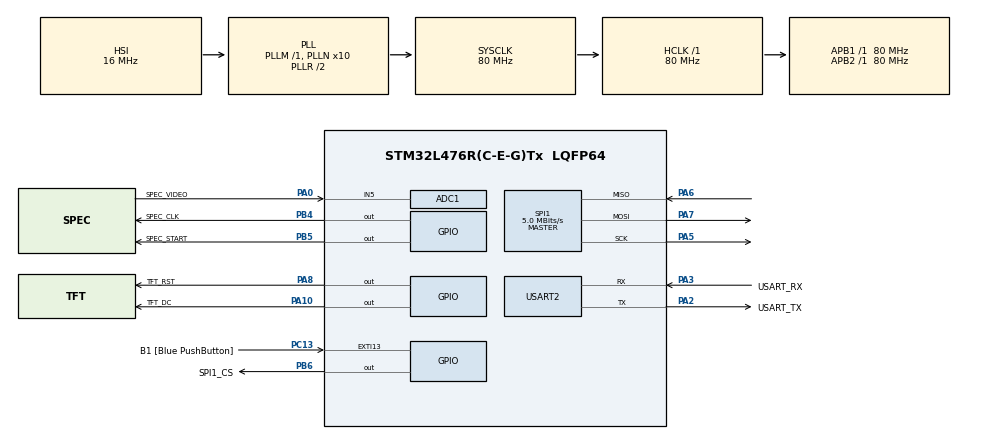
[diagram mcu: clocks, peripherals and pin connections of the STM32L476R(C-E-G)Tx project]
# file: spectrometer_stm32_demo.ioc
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ADC1.Channel-0\#ChannelRegularConversion=ADC_CHANNEL_5
ADC1.NbrOfConversionFlag=1
ADC1.OffsetNumber-0\#ChannelRegularConversion=ADC_OFFSET_NONE
ADC1.Rank-0\#ChannelRegularConversion=1
ADC1.SamplingTime-0\#ChannelRegularConversion=ADC_SAMPLETIME_2CYCLES_5
ADC1.master=1
Mcu.Family=STM32L4
Mcu.Name=STM32L476R(C-E-G)Tx
Mcu.Package=LQFP64
NVIC.PriorityGroup=NVIC_PRIORITYGROUP_4
PA0.GPIO_Label=SPEC_VIDEO
PA0.Signal=ADCx_IN5
PA10.GPIO_Label=TFT_DC
PA10.Signal=GPIO_Output
PA13\ (JTMS-SWDIO).GPIO_Label=TMS
PA13\ (JTMS-SWDIO).Mode=Serial_Wire
PA13\ (JTMS-SWDIO).Signal=SYS_JTMS-SWDIO
PA14\ (JTCK-SWCLK).GPIO_Label=TCK
PA14\ (JTCK-SWCLK).Mode=Serial_Wire
PA14\ (JTCK-SWCLK).Signal=SYS_JTCK-SWCLK
PA2.GPIO_Label=USART_TX
PA2.GPIO_Mode=GPIO_MODE_AF_PP
PA2.GPIO_PuPd=GPIO_NOPULL
PA2.GPIO_Speed=GPIO_SPEED_FREQ_VERY_HIGH
PA2.Mode=Asynchronous
PA2.Signal=USART2_TX
PA3.GPIO_Label=USART_RX
PA3.GPIO_Mode=GPIO_MODE_AF_PP
PA3.GPIO_PuPd=GPIO_NOPULL
PA3.GPIO_Speed=GPIO_SPEED_FREQ_VERY_HIGH
PA3.Mode=Asynchronous
PA3.Signal=USART2_RX
PA5.Mode=Full_Duplex_Master
PA5.Signal=SPI1_SCK
PA6.Mode=Full_Duplex_Master
PA6.Signal=SPI1_MISO
PA7.Mode=Full_Duplex_Master
PA7.Signal=SPI1_MOSI
PA8.GPIO_Label=TFT_RST
PA8.Signal=GPIO_Output
PB3\ (JTDO-TRACESWO).GPIO_Label=SWO
PB3\ (JTDO-TRACESWO).Signal=SYS_JTDO-SWO
PB4\ (NJTRST).GPIO_Label=SPEC_CLK
PB4\ (NJTRST).Signal=GPIO_Output
PB5.GPIO_Label=SPEC_START
PB5.Signal=GPIO_Output
PB6.GPIO_Label=SPI1_CS
PB6.Signal=GPIO_Output
PC13.GPIO_Label=B1 [Blue PushButton]
PC13.GPIO_ModeDefaultEXTI=GPIO_MODE_IT_FALLING
PC13.GPIO_PuPd=GPIO_NOPULL
PC13.Signal=GPXTI13
PC14-OSC32_IN\ (PC14).Mode=LSE-External-Oscillator
PC14-OSC32_IN\ (PC14).Signal=RCC_OSC32_IN
PC15-OSC32_OUT\ (PC15).Mode=LSE-External-Oscillator
PC15-OSC32_OUT\ (PC15).Signal=RCC_OSC32_OUT
PH0-OSC_IN\ (PH0).Signal=RCC_OSC_IN
PH1-OSC_OUT\ (PH1).Signal=RCC_OSC_OUT
ProjectManager.HeapSize=0x200
ProjectManager.StackSize=0x400
ProjectManager.TargetToolchain=STM32CubeIDE
RCC.ADCFreq_Value=64000000
RCC.AHBFreq_Value=80000000
RCC.APB1Freq_Value=80000000
RCC.APB1TimFreq_Value=80000000
RCC.APB2Freq_Value=80000000
RCC.APB2TimFreq_Value=80000000
RCC.CortexFreq_Value=80000000
RCC.HCLKFreq_Value=80000000
RCC.HSE_VALUE=8000000
RCC.HSI_VALUE=16000000
RCC.MSI_VALUE=4000000
RCC.PLLN=10
RCC.PLLSourceVirtual=RCC_PLLSOURCE_HSI
RCC.PREFETCH_ENABLE=1
RCC.SYSCLKFreq_VALUE=80000000
RCC.SYSCLKSource=RCC_SYSCLKSOURCE_PLLCLK
RCC.USBFreq_Value=64000000
RCC.VCOOutputFreq_Value=160000000
SH.ADCx_IN5.0=ADC1_IN5,IN5-Single-Ended
SPI1.BaudRatePrescaler=SPI_BAUDRATEPRESCALER_16
SPI1.CalculateBaudRate=5.0 MBits/s
SPI1.DataSize=SPI_DATASIZE_8BIT
SPI1.Direction=SPI_DIRECTION_2LINES
SPI1.Mode=SPI_MODE_MASTER
SPI1.NSSPMode=SPI_NSS_PULSE_DISABLE
SPI1.VirtualType=VM_MASTER
TIM2.Prescaler=80-1
USART2.VirtualMode-Asynchronous=VM_ASYNC
VP_TIM2_VS_ClockSourceINT.Mode=Internal
board=NUCLEO-L476RG

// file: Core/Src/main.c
/* USER CODE BEGIN Header */
/**
  ******************************************************************************
  * @file           : main.c
  * @brief          : Main program body
  ******************************************************************************
  * @attention
  *
  * <h2><center>&copy; Copyright (c) 2022 STMicroelectronics.
  * All rights reserved.</center></h2>
  *
  * This software component is licensed by ST under BSD 3-Clause license,
  * the "License"; You may not use this file except in compliance with the
  * License. You may obtain a copy of the License at:
  *                        opensource.org/licenses/BSD-3-Clause
  *
  ******************************************************************************
  */
/* USER CODE END Header */
#include "main.h"

/* USER CODE BEGIN Includes */
#include "ili9341_display.h"
#include "spectrometer.h"
/* USER CODE END Includes */

ADC_HandleTypeDef hadc1;

SPI_HandleTypeDef hspi1;

TIM_HandleTypeDef htim2;

UART_HandleTypeDef huart2;

void SystemClock_Config(void);
static void MX_GPIO_Init(void);
static void MX_USART2_UART_Init(void);
static void MX_SPI1_Init(void);
static void MX_TIM2_Init(void);
static void MX_ADC1_Init(void);

int main(void)
{

  /* MCU Configuration--------------------------------------------------------*/

  /* Reset of all peripherals, Initializes the Flash interface and the Systick. */
  HAL_Init();

  /* Configure the system clock */
  SystemClock_Config();

  /* Initialize all configured peripherals */
  MX_GPIO_Init();
  MX_USART2_UART_Init();
  MX_SPI1_Init();
  MX_TIM2_Init();
  MX_ADC1_Init();
  /* USER CODE BEGIN 2 */
  ILI9341_Init();
  //ILI9341_Set_Rotation(SCREEN_HORIZONTAL_1); //todo:!
  spectrometerInit();
  /* USER CODE END 2 */

  /* Infinite loop */
  while (1)
  {

    /* USER CODE BEGIN 3 */
	  runSpectrometer();
  }
  /* USER CODE END 3 */
}

void SystemClock_Config(void)
{
  RCC_OscInitTypeDef RCC_OscInitStruct = {0};
  RCC_ClkInitTypeDef RCC_ClkInitStruct = {0};
  RCC_PeriphCLKInitTypeDef PeriphClkInit = {0};

  /** Initializes the RCC Oscillators according to the specified parameters
  * in the RCC_OscInitTypeDef structure.
  */
  RCC_OscInitStruct.OscillatorType = RCC_OSCILLATORTYPE_HSI;
  RCC_OscInitStruct.HSIState = RCC_HSI_ON;
  RCC_OscInitStruct.HSICalibrationValue = RCC_HSICALIBRATION_DEFAULT;
  RCC_OscInitStruct.PLL.PLLState = RCC_PLL_ON;
  RCC_OscInitStruct.PLL.PLLSource = RCC_PLLSOURCE_HSI;
  RCC_OscInitStruct.PLL.PLLM = 1;
  RCC_OscInitStruct.PLL.PLLN = 10;
  RCC_OscInitStruct.PLL.PLLP = RCC_PLLP_DIV7;
  RCC_OscInitStruct.PLL.PLLQ = RCC_PLLQ_DIV2;
  RCC_OscInitStruct.PLL.PLLR = RCC_PLLR_DIV2;
  if (HAL_RCC_OscConfig(&RCC_OscInitStruct) != HAL_OK)
  {
    Error_Handler();
  }
  /** Initializes the CPU, AHB and APB buses clocks
  */
  RCC_ClkInitStruct.ClockType = RCC_CLOCKTYPE_HCLK|RCC_CLOCKTYPE_SYSCLK
                              |RCC_CLOCKTYPE_PCLK1|RCC_CLOCKTYPE_PCLK2;
  RCC_ClkInitStruct.SYSCLKSource = RCC_SYSCLKSOURCE_PLLCLK;
  RCC_ClkInitStruct.AHBCLKDivider = RCC_SYSCLK_DIV1;
  RCC_ClkInitStruct.APB1CLKDivider = RCC_HCLK_DIV1;
  RCC_ClkInitStruct.APB2CLKDivider = RCC_HCLK_DIV1;

  if (HAL_RCC_ClockConfig(&RCC_ClkInitStruct, FLASH_LATENCY_4) != HAL_OK)
  {
    Error_Handler();
  }
  PeriphClkInit.PeriphClockSelection = RCC_PERIPHCLK_USART2|RCC_PERIPHCLK_ADC;
  PeriphClkInit.Usart2ClockSelection = RCC_USART2CLKSOURCE_PCLK1;
  PeriphClkInit.AdcClockSelection = RCC_ADCCLKSOURCE_PLLSAI1;
  PeriphClkInit.PLLSAI1.PLLSAI1Source = RCC_PLLSOURCE_HSI;
  PeriphClkInit.PLLSAI1.PLLSAI1M = 1;
  PeriphClkInit.PLLSAI1.PLLSAI1N = 8;
  PeriphClkInit.PLLSAI1.PLLSAI1P = RCC_PLLP_DIV7;
  PeriphClkInit.PLLSAI1.PLLSAI1Q = RCC_PLLQ_DIV2;
  PeriphClkInit.PLLSAI1.PLLSAI1R = RCC_PLLR_DIV2;
  PeriphClkInit.PLLSAI1.PLLSAI1ClockOut = RCC_PLLSAI1_ADC1CLK;
  if (HAL_RCCEx_PeriphCLKConfig(&PeriphClkInit) != HAL_OK)
  {
    Error_Handler();
  }
  /** Configure the main internal regulator output voltage
  */
  if (HAL_PWREx_ControlVoltageScaling(PWR_REGULATOR_VOLTAGE_SCALE1) != HAL_OK)
  {
    Error_Handler();
  }
}

static void MX_ADC1_Init(void)
{

  ADC_MultiModeTypeDef multimode = {0};
  ADC_ChannelConfTypeDef sConfig = {0};

  /** Common config
  */
  hadc1.Instance = ADC1;
  hadc1.Init.ClockPrescaler = ADC_CLOCK_ASYNC_DIV1;
  hadc1.Init.Resolution = ADC_RESOLUTION_12B;
  hadc1.Init.DataAlign = ADC_DATAALIGN_RIGHT;
  hadc1.Init.ScanConvMode = ADC_SCAN_DISABLE;
  hadc1.Init.EOCSelection = ADC_EOC_SINGLE_CONV;
  hadc1.Init.LowPowerAutoWait = DISABLE;
  hadc1.Init.ContinuousConvMode = DISABLE;
  hadc1.Init.NbrOfConversion = 1;
  hadc1.Init.DiscontinuousConvMode = DISABLE;
  hadc1.Init.ExternalTrigConv = ADC_SOFTWARE_START;
  hadc1.Init.ExternalTrigConvEdge = ADC_EXTERNALTRIGCONVEDGE_NONE;
  hadc1.Init.DMAContinuousRequests = DISABLE;
  hadc1.Init.Overrun = ADC_OVR_DATA_PRESERVED;
  hadc1.Init.OversamplingMode = DISABLE;
  if (HAL_ADC_Init(&hadc1) != HAL_OK)
  {
    Error_Handler();
  }
  /** Configure the ADC multi-mode
  */
  multimode.Mode = ADC_MODE_INDEPENDENT;
  if (HAL_ADCEx_MultiModeConfigChannel(&hadc1, &multimode) != HAL_OK)
  {
    Error_Handler();
  }
  /** Configure Regular Channel
  */
  sConfig.Channel = ADC_CHANNEL_5;
  sConfig.Rank = ADC_REGULAR_RANK_1;
  sConfig.SamplingTime = ADC_SAMPLETIME_2CYCLES_5;
  sConfig.SingleDiff = ADC_SINGLE_ENDED;
  sConfig.OffsetNumber = ADC_OFFSET_NONE;
  sConfig.Offset = 0;
  if (HAL_ADC_ConfigChannel(&hadc1, &sConfig) != HAL_OK)
  {
    Error_Handler();
  }

}

static void MX_SPI1_Init(void)
{

  /* SPI1 parameter configuration*/
  hspi1.Instance = SPI1;
  hspi1.Init.Mode = SPI_MODE_MASTER;
  hspi1.Init.Direction = SPI_DIRECTION_2LINES;
  hspi1.Init.DataSize = SPI_DATASIZE_8BIT;
  hspi1.Init.CLKPolarity = SPI_POLARITY_LOW;
  hspi1.Init.CLKPhase = SPI_PHASE_1EDGE;
  hspi1.Init.NSS = SPI_NSS_SOFT;
  hspi1.Init.BaudRatePrescaler = SPI_BAUDRATEPRESCALER_16;
  hspi1.Init.FirstBit = SPI_FIRSTBIT_MSB;
  hspi1.Init.TIMode = SPI_TIMODE_DISABLE;
  hspi1.Init.CRCCalculation = SPI_CRCCALCULATION_DISABLE;
  hspi1.Init.CRCPolynomial = 7;
  hspi1.Init.CRCLength = SPI_CRC_LENGTH_DATASIZE;
  hspi1.Init.NSSPMode = SPI_NSS_PULSE_DISABLE;
  if (HAL_SPI_Init(&hspi1) != HAL_OK)
  {
    Error_Handler();
  }

}

static void MX_TIM2_Init(void)
{

  TIM_ClockConfigTypeDef sClockSourceConfig = {0};
  TIM_MasterConfigTypeDef sMasterConfig = {0};

  htim2.Instance = TIM2;
  htim2.Init.Prescaler = 80-1;
  htim2.Init.CounterMode = TIM_COUNTERMODE_UP;
  htim2.Init.Period = 4294967295;
  htim2.Init.ClockDivision = TIM_CLOCKDIVISION_DIV1;
  htim2.Init.AutoReloadPreload = TIM_AUTORELOAD_PRELOAD_DISABLE;
  if (HAL_TIM_Base_Init(&htim2) != HAL_OK)
  {
    Error_Handler();
  }
  sClockSourceConfig.ClockSource = TIM_CLOCKSOURCE_INTERNAL;
  if (HAL_TIM_ConfigClockSource(&htim2, &sClockSourceConfig) != HAL_OK)
  {
    Error_Handler();
  }
  sMasterConfig.MasterOutputTrigger = TIM_TRGO_RESET;
  sMasterConfig.MasterSlaveMode = TIM_MASTERSLAVEMODE_DISABLE;
  if (HAL_TIMEx_MasterConfigSynchronization(&htim2, &sMasterConfig) != HAL_OK)
  {
    Error_Handler();
  }
  /* USER CODE BEGIN TIM2_Init 2 */
  HAL_TIM_Base_Start (&htim2);
  /* USER CODE END TIM2_Init 2 */

}

static void MX_USART2_UART_Init(void)
{

  huart2.Instance = USART2;
  huart2.Init.BaudRate = 115200;
  huart2.Init.WordLength = UART_WORDLENGTH_8B;
  huart2.Init.StopBits = UART_STOPBITS_1;
  huart2.Init.Parity = UART_PARITY_NONE;
  huart2.Init.Mode = UART_MODE_TX_RX;
  huart2.Init.HwFlowCtl = UART_HWCONTROL_NONE;
  huart2.Init.OverSampling = UART_OVERSAMPLING_16;
  huart2.Init.OneBitSampling = UART_ONE_BIT_SAMPLE_DISABLE;
  huart2.AdvancedInit.AdvFeatureInit = UART_ADVFEATURE_NO_INIT;
  if (HAL_UART_Init(&huart2) != HAL_OK)
  {
    Error_Handler();
  }

}

static void MX_GPIO_Init(void)
{
  GPIO_InitTypeDef GPIO_InitStruct = {0};

  /* GPIO Ports Clock Enable */
  __HAL_RCC_GPIOC_CLK_ENABLE();
  __HAL_RCC_GPIOH_CLK_ENABLE();
  __HAL_RCC_GPIOA_CLK_ENABLE();
  __HAL_RCC_GPIOB_CLK_ENABLE();

  /*Configure GPIO pin Output Level */
  HAL_GPIO_WritePin(GPIOA, TFT_RST_Pin|TFT_DC_Pin, GPIO_PIN_RESET);

  /*Configure GPIO pin Output Level */
  HAL_GPIO_WritePin(GPIOB, SPEC_CLK_Pin|SPEC_START_Pin|SPI1_CS_Pin, GPIO_PIN_RESET);

  /*Configure GPIO pin : B1_Pin */
  GPIO_InitStruct.Pin = B1_Pin;
  GPIO_InitStruct.Mode = GPIO_MODE_IT_FALLING;
  GPIO_InitStruct.Pull = GPIO_NOPULL;
  HAL_GPIO_Init(B1_GPIO_Port, &GPIO_InitStruct);

  /*Configure GPIO pins : TFT_RST_Pin TFT_DC_Pin */
  GPIO_InitStruct.Pin = TFT_RST_Pin|TFT_DC_Pin;
  GPIO_InitStruct.Mode = GPIO_MODE_OUTPUT_PP;
  GPIO_InitStruct.Pull = GPIO_NOPULL;
  GPIO_InitStruct.Speed = GPIO_SPEED_FREQ_LOW;
  HAL_GPIO_Init(GPIOA, &GPIO_InitStruct);

  /*Configure GPIO pins : SPEC_CLK_Pin SPEC_START_Pin SPI1_CS_Pin */
  GPIO_InitStruct.Pin = SPEC_CLK_Pin|SPEC_START_Pin|SPI1_CS_Pin;
  GPIO_InitStruct.Mode = GPIO_MODE_OUTPUT_PP;
  GPIO_InitStruct.Pull = GPIO_NOPULL;
  GPIO_InitStruct.Speed = GPIO_SPEED_FREQ_LOW;
  HAL_GPIO_Init(GPIOB, &GPIO_InitStruct);

}

void Error_Handler(void)
{
}

/************************ (C) COPYRIGHT STMicroelectronics *****END OF FILE****/
